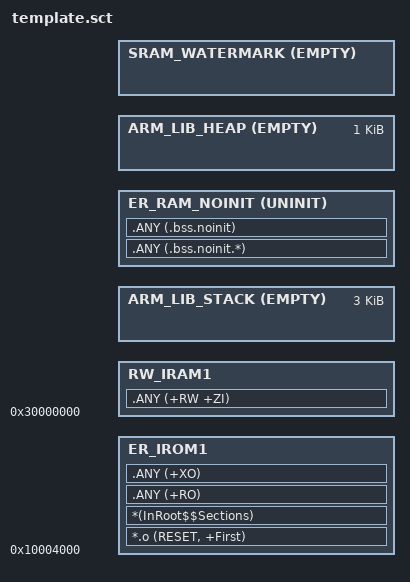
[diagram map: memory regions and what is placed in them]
#! armclang --target=arm-arm-none-eabi -march=armv8.1-m.main -E -xc
; *************************************************************
; *** Scatter-Loading Description File generated by uVision ***
; *************************************************************

#define ROM_BASE_ADDRESS        0x10000000
#define ROM_SIZE                0x00200000

#define BOOTLOADER_SIZE         (1024*16)

#define APP_BASE_ADDRESS        (ROM_BASE_ADDRESS + BOOTLOADER_SIZE)
#define APP_SIZE                (ROM_SIZE - BOOTLOADER_SIZE)


LR_IROM1 APP_BASE_ADDRESS APP_SIZE  {    ; load region size_region

    ER_IROM1 +0  {  ; load address = execution address
        *.o (RESET, +First)
        *(InRoot$$Sections)
        .ANY (+RO)
        .ANY (+XO)
    }

    RW_IRAM1 0x30000000  {  ; RW data
        .ANY (+RW +ZI)
    }

    ARM_LIB_STACK +0 ALIGN 8 EMPTY 0x0C00 {
    }

    ER_RAM_NOINIT +0 UNINIT {
        .ANY (.bss.noinit.*)
        .ANY (.bss.noinit)
    }

    ARM_LIB_HEAP +0 ALIGN 8 EMPTY 0x0400 {
    }

    /* This empty, zero long execution region is here to mark the limit address
     * of the last execution region that is allocated in SRAM.
     */
    SRAM_WATERMARK +0 EMPTY 0x0 {
    }
}

